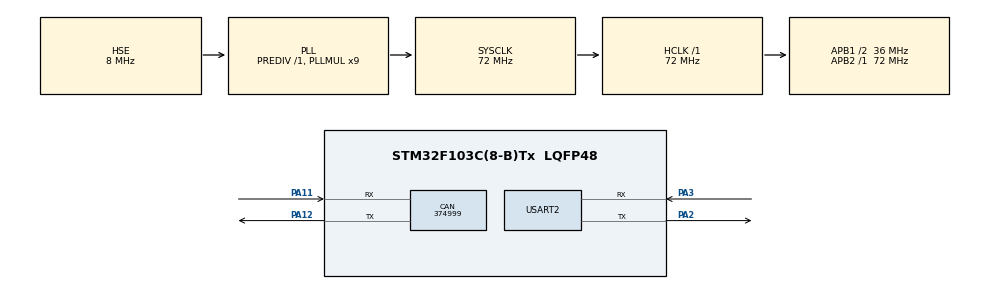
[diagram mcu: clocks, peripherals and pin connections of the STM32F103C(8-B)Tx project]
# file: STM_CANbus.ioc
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CAN.BS1=CAN_BS1_4TQ
CAN.CalculateBaudRate=374999
CAN.CalculateTimeBit=2666
CAN.CalculateTimeQuantum=444.44444444444446
Dma.Request0=USART2_TX
Dma.Request1=USART2_RX
Dma.USART2_RX.1.Direction=DMA_PERIPH_TO_MEMORY
Dma.USART2_RX.1.Instance=DMA1_Channel6
Dma.USART2_RX.1.MemDataAlignment=DMA_MDATAALIGN_BYTE
Dma.USART2_RX.1.MemInc=DMA_MINC_ENABLE
Dma.USART2_RX.1.Mode=DMA_NORMAL
Dma.USART2_RX.1.PeriphDataAlignment=DMA_PDATAALIGN_BYTE
Dma.USART2_RX.1.PeriphInc=DMA_PINC_DISABLE
Dma.USART2_RX.1.Priority=DMA_PRIORITY_LOW
Dma.USART2_TX.0.Direction=DMA_MEMORY_TO_PERIPH
Dma.USART2_TX.0.Instance=DMA1_Channel7
Dma.USART2_TX.0.MemDataAlignment=DMA_MDATAALIGN_BYTE
Dma.USART2_TX.0.MemInc=DMA_MINC_ENABLE
Dma.USART2_TX.0.Mode=DMA_NORMAL
Dma.USART2_TX.0.PeriphDataAlignment=DMA_PDATAALIGN_BYTE
Dma.USART2_TX.0.PeriphInc=DMA_PINC_DISABLE
Dma.USART2_TX.0.Priority=DMA_PRIORITY_LOW
Mcu.Family=STM32F1
Mcu.Name=STM32F103C(8-B)Tx
Mcu.Package=LQFP48
NVIC.DMA1_Channel6_IRQn=true\:0\:0\:false\:false\:true\:false\:true\:true
NVIC.DMA1_Channel7_IRQn=true\:0\:0\:false\:false\:true\:false\:true\:true
NVIC.PriorityGroup=NVIC_PRIORITYGROUP_4
NVIC.USART2_IRQn=true\:0\:0\:false\:false\:true\:true\:true\:true
NVIC.USB_LP_CAN1_RX0_IRQn=true\:0\:0\:false\:false\:true\:true\:true\:true
PA11.Mode=CAN_Activate
PA11.Signal=CAN_RX
PA12.Mode=CAN_Activate
PA12.Signal=CAN_TX
PA2.Mode=Asynchronous
PA2.Signal=USART2_TX
PA3.Mode=Asynchronous
PA3.Signal=USART2_RX
PD0-OSC_IN.Mode=HSE-External-Oscillator
PD0-OSC_IN.Signal=RCC_OSC_IN
PD1-OSC_OUT.Mode=HSE-External-Oscillator
PD1-OSC_OUT.Signal=RCC_OSC_OUT
ProjectManager.HeapSize=0x200
ProjectManager.StackSize=0x400
ProjectManager.TargetToolchain=MDK-ARM V5
RCC.AHBFreq_Value=72000000
RCC.APB1CLKDivider=RCC_HCLK_DIV2
RCC.APB1Freq_Value=36000000
RCC.APB1TimFreq_Value=72000000
RCC.APB2Freq_Value=72000000
RCC.APB2TimFreq_Value=72000000
RCC.HCLKFreq_Value=72000000
RCC.PLLMUL=RCC_PLL_MUL9
RCC.PLLSourceVirtual=RCC_PLLSOURCE_HSE
RCC.SYSCLKFreq_VALUE=72000000
RCC.SYSCLKSource=RCC_SYSCLKSOURCE_PLLCLK
RCC.USBFreq_Value=72000000
USART2.VirtualMode=VM_ASYNC
VP_SYS_VS_ND.Mode=No_Debug
board=custom

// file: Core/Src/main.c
/* USER CODE BEGIN Header */
/**
  ******************************************************************************
  * @file           : main.c
  * @brief          : Main program body
  ******************************************************************************
  * @attention
  *
  * Copyright (c) 2023 STMicroelectronics.
  * All rights reserved.
  *
  * This software is licensed under terms that can be found in the LICENSE file
  * in the root directory of this software component.
  * If no LICENSE file comes with this software, it is provided AS-IS.
  *
  ******************************************************************************
  */
/* USER CODE END Header */
#include "main.h"
#include "stdint.h"

CAN_HandleTypeDef hcan;

UART_HandleTypeDef huart2;
DMA_HandleTypeDef hdma_usart2_tx;
DMA_HandleTypeDef hdma_usart2_rx;

/*Khai bao cac buffer cho CAN va UART
 */

CAN_TxHeaderTypeDef  myTxMessage;
CAN_RxHeaderTypeDef myRxMessage;
CAN_FilterTypeDef myFilterConfig;
uint8_t checkTx=0;
uint8_t checkRx=0;

void SystemClock_Config(void);
static void MX_GPIO_Init(void);
static void MX_DMA_Init(void);
static void MX_USART2_UART_Init(void);
static void MX_CAN_Init(void);
/* USER CODE BEGIN PFP */
static void CAN_FilterConfig(void);
/* USER CODE END PFP */

int main(void)
{

  /* MCU Configuration--------------------------------------------------------*/

  /* Reset of all peripherals, Initializes the Flash interface and the Systick. */
  HAL_Init();

  /* Configure the system clock */
  SystemClock_Config();

  /* Initialize all configured peripherals */
  MX_GPIO_Init();
  MX_DMA_Init();
  MX_USART2_UART_Init();
  MX_CAN_Init();
  /* USER CODE BEGIN 2 */
  hcan.Init.
  /* USER CODE END 2 */

  /* Infinite loop */
  while (1)
  {

  }
}

void SystemClock_Config(void)
{
  RCC_OscInitTypeDef RCC_OscInitStruct = {0};
  RCC_ClkInitTypeDef RCC_ClkInitStruct = {0};

  /** Initializes the RCC Oscillators according to the specified parameters
  * in the RCC_OscInitTypeDef structure.
  */
  RCC_OscInitStruct.OscillatorType = RCC_OSCILLATORTYPE_HSE;
  RCC_OscInitStruct.HSEState = RCC_HSE_ON;
  RCC_OscInitStruct.HSEPredivValue = RCC_HSE_PREDIV_DIV1;
  RCC_OscInitStruct.HSIState = RCC_HSI_ON;
  RCC_OscInitStruct.PLL.PLLState = RCC_PLL_ON;
  RCC_OscInitStruct.PLL.PLLSource = RCC_PLLSOURCE_HSE;
  RCC_OscInitStruct.PLL.PLLMUL = RCC_PLL_MUL9;
  if (HAL_RCC_OscConfig(&RCC_OscInitStruct) != HAL_OK)
  {
    Error_Handler();
  }

  /** Initializes the CPU, AHB and APB buses clocks
  */
  RCC_ClkInitStruct.ClockType = RCC_CLOCKTYPE_HCLK|RCC_CLOCKTYPE_SYSCLK
                              |RCC_CLOCKTYPE_PCLK1|RCC_CLOCKTYPE_PCLK2;
  RCC_ClkInitStruct.SYSCLKSource = RCC_SYSCLKSOURCE_PLLCLK;
  RCC_ClkInitStruct.AHBCLKDivider = RCC_SYSCLK_DIV1;
  RCC_ClkInitStruct.APB1CLKDivider = RCC_HCLK_DIV2;
  RCC_ClkInitStruct.APB2CLKDivider = RCC_HCLK_DIV1;

  if (HAL_RCC_ClockConfig(&RCC_ClkInitStruct, FLASH_LATENCY_2) != HAL_OK)
  {
    Error_Handler();
  }
}

static void MX_CAN_Init(void)
{

  hcan.Instance = CAN1;
  hcan.Init.Prescaler = 16;
  hcan.Init.Mode = CAN_MODE_NORMAL;
  hcan.Init.SyncJumpWidth = CAN_SJW_1TQ;
  hcan.Init.TimeSeg1 = CAN_BS1_4TQ;
  hcan.Init.TimeSeg2 = CAN_BS2_1TQ;
  hcan.Init.TimeTriggeredMode = DISABLE;
  hcan.Init.AutoBusOff = DISABLE;
  hcan.Init.AutoWakeUp = DISABLE;
  hcan.Init.AutoRetransmission = DISABLE;
  hcan.Init.ReceiveFifoLocked = DISABLE;
  hcan.Init.TransmitFifoPriority = DISABLE;
  if (HAL_CAN_Init(&hcan) != HAL_OK)
  {
    Error_Handler();
  }

}

//setup filter ??
static void CAN_FilterConfig(void)
{
	myFilterConfig.FilterMode=CAN_FILTERMODE_IDMASK;
	myFilterConfig.FilterScale=CAN_FILTERSCALE_32BIT;
	myFilterConfig.FilterIdHigh=0x0000;
	myFilterConfig.FilterIdLow=0;
	myFilterConfig.FilterMaskIdHigh=0;
	myFilterConfig.FilterMaskIdLow=0;
	myFilterConfig.FilterFIFOAssignment=ENABLE;
	myFilterConfig.FilterBank=14;
	HAL_CAN_ConfigFilter(&hcan, &myFilterConfig);

}

static void CAN_SetupProtocol(void)
{

}
static void MX_USART2_UART_Init(void)
{

  huart2.Instance = USART2;
  huart2.Init.BaudRate = 115200;
  huart2.Init.WordLength = UART_WORDLENGTH_8B;
  huart2.Init.StopBits = UART_STOPBITS_1;
  huart2.Init.Parity = UART_PARITY_NONE;
  huart2.Init.Mode = UART_MODE_TX_RX;
  huart2.Init.HwFlowCtl = UART_HWCONTROL_NONE;
  huart2.Init.OverSampling = UART_OVERSAMPLING_16;
  if (HAL_UART_Init(&huart2) != HAL_OK)
  {
    Error_Handler();
  }

}

static void MX_DMA_Init(void)
{

  /* DMA controller clock enable */
  __HAL_RCC_DMA1_CLK_ENABLE();

  /* DMA interrupt init */
  /* DMA1_Channel6_IRQn interrupt configuration */
  HAL_NVIC_SetPriority(DMA1_Channel6_IRQn, 0, 0);
  HAL_NVIC_EnableIRQ(DMA1_Channel6_IRQn);
  /* DMA1_Channel7_IRQn interrupt configuration */
  HAL_NVIC_SetPriority(DMA1_Channel7_IRQn, 0, 0);
  HAL_NVIC_EnableIRQ(DMA1_Channel7_IRQn);

}

static void MX_GPIO_Init(void)
{

  /* GPIO Ports Clock Enable */
  __HAL_RCC_GPIOD_CLK_ENABLE();
  __HAL_RCC_GPIOA_CLK_ENABLE();

}

void Error_Handler(void)
{
  __disable_irq();
  while (1)
  {
  }
}
